# STM32L562 register map
File version: 1.0
CPU: CM33 r0p1, little endian, MPU, FPU, 3 interrupt priority bits
Registers are 32-bit, read-write, reset 0x0 unless marked. A register's access mark holds for its fields unless they carry their own. Offsets are from the block's base; [hi:lo] are bit positions; {n}, {i} and the like mark numbered series.

## GTZC_MPCBB1
Base 0x40032C00
Same registers: GTZC_MPCBB2 0x40033000, SEC_GTZC_MPCBB1 0x50032C00, SEC_GTZC_MPCBB2 0x50033000
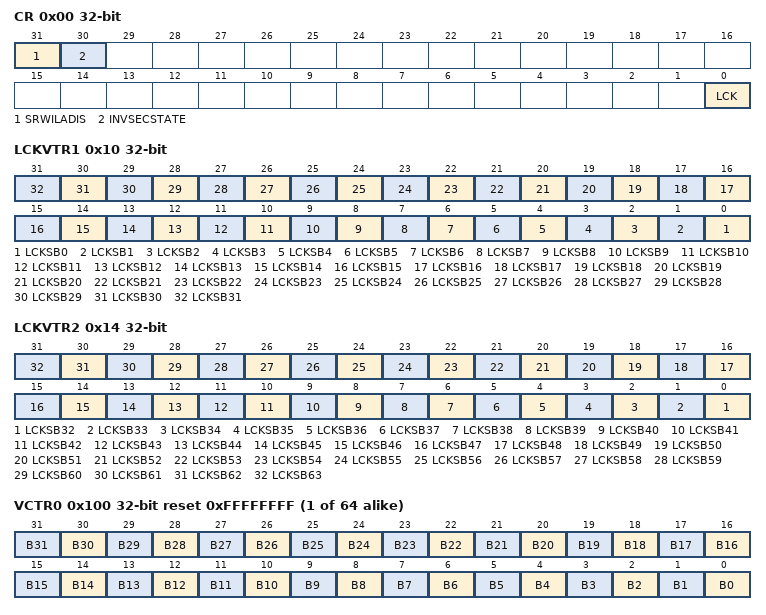
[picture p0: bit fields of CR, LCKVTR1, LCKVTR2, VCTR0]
0x00 CR — MPCBB control register
  [31] SRWILADIS, [30] INVSECSTATE, [0] LCK
0x10 LCKVTR1 — MPCBB control register
  [n] LCKSB{n} (n=0..31)
0x14 LCKVTR2 — MPCBB control register
  [n-32] LCKSB{n} (n=32..63)
{0x100+4i} VCTR{i} (i=0..63) reset 0xFFFFFFFF — MPCBBx vector register
  [n] B{n} (n=0..31)

## GTZC_TZIC
Base 0x40032800
Same registers: SEC_GTZC_TZIC 0x50032800
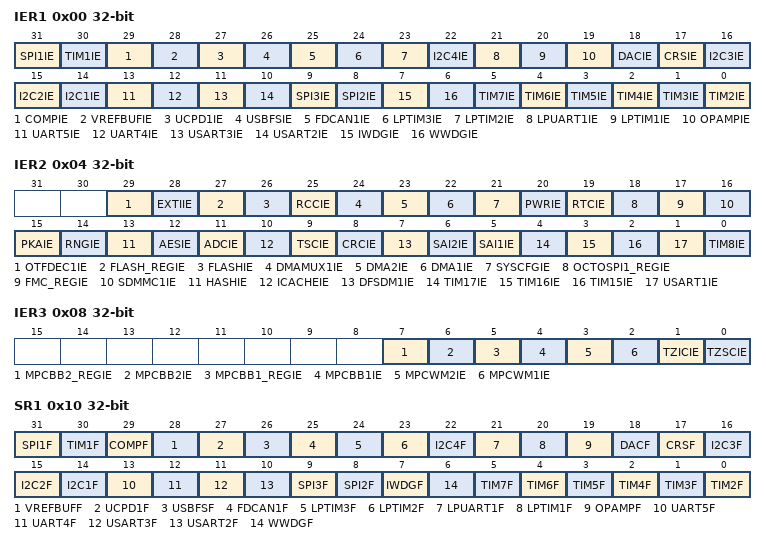
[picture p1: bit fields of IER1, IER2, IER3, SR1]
0x00 IER1 — TZIC interrupt enable register 1
  [31] SPI1IE, [30] TIM1IE, [29] COMPIE, [28] VREFBUFIE, [27] UCPD1IE, [26] USBFSIE, [25] FDCAN1IE, [24] LPTIM3IE, [23] LPTIM2IE, [22] I2C4IE, [21] LPUART1IE, [20] LPTIM1IE, [19] OPAMPIE, [18] DACIE, [17] CRSIE, [16] I2C3IE, [15] I2C2IE, [14] I2C1IE, [13] UART5IE, [12] UART4IE, [11] USART3IE, [10] USART2IE, [9] SPI3IE, [8] SPI2IE, [7] IWDGIE, [6] WWDGIE, [n-2] TIM{n}IE (n=2..7)
0x04 IER2 — TZIC interrupt enable register 2
  [29] OTFDEC1IE, [28] EXTIIE, [27] FLASH_REGIE, [26] FLASHIE, [25] RCCIE, [24] DMAMUX1IE, [23] DMA2IE, [22] DMA1IE, [21] SYSCFGIE, [20] PWRIE, [19] RTCIE, [18] OCTOSPI1_REGIE, [17] FMC_REGIE, [16] SDMMC1IE, [15] PKAIE, [14] RNGIE, [13] HASHIE, [12] AESIE, [11] ADCIE, [10] ICACHEIE, [9] TSCIE, [8] CRCIE, [7] DFSDM1IE, [6] SAI2IE, [5] SAI1IE, [4] TIM17IE, [3] TIM16IE, [2] TIM15IE, [1] USART1IE, [0] TIM8IE
0x08 IER3 — TZIC interrupt enable register 3
  [7] MPCBB2_REGIE, [6] MPCBB2IE, [5] MPCBB1_REGIE, [4] MPCBB1IE, [3] MPCWM2IE, [2] MPCWM1IE, [1] TZICIE, [0] TZSCIE
0x10 SR1 ro — TZIC interrupt status register 1
  [31] SPI1F, [30] TIM1F, [29] COMPF, [28] VREFBUFF, [27] UCPD1F, [26] USBFSF, [25] FDCAN1F, [24] LPTIM3F, [23] LPTIM2F, [22] I2C4F, [21] LPUART1F, [20] LPTIM1F, [19] OPAMPF, [18] DACF, [17] CRSF, [16] I2C3F, [15] I2C2F, [14] I2C1F, [13] UART5F, [12] UART4F, [11] USART3F, [10] USART2F, [9] SPI3F, [8] SPI2F, [7] IWDGF, [6] WWDGF, [n-2] TIM{n}F (n=2..7)
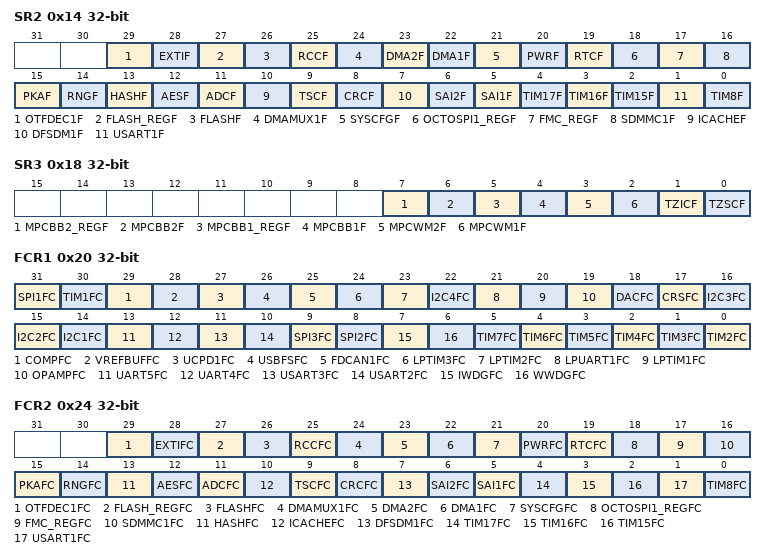
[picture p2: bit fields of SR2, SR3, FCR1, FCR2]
0x14 SR2 — TZIC interrupt status register 2
  [29] OTFDEC1F, [28] EXTIF, [27] FLASH_REGF, [26] FLASHF, [25] RCCF, [24] DMAMUX1F, [23] DMA2F, [22] DMA1F, [21] SYSCFGF, [20] PWRF, [19] RTCF, [18] OCTOSPI1_REGF, [17] FMC_REGF, [16] SDMMC1F, [15] PKAF, [14] RNGF, [13] HASHF, [12] AESF, [11] ADCF, [10] ICACHEF, [9] TSCF, [8] CRCF, [7] DFSDM1F, [6] SAI2F, [5] SAI1F, [4] TIM17F, [3] TIM16F, [2] TIM15F, [1] USART1F, [0] TIM8F
0x18 SR3 — TZIC interrupt status register 3
  [7] MPCBB2_REGF, [6] MPCBB2F, [5] MPCBB1_REGF, [4] MPCBB1F, [3] MPCWM2F, [2] MPCWM1F, [1] TZICF, [0] TZSCF
0x20 FCR1 wo — TZIC interrupt clear register 1
  [31] SPI1FC, [30] TIM1FC, [29] COMPFC, [28] VREFBUFFC, [27] UCPD1FC, [26] USBFSFC, [25] FDCAN1FC, [24] LPTIM3FC, [23] LPTIM2FC, [22] I2C4FC, [21] LPUART1FC, [20] LPTIM1FC, [19] OPAMPFC, [18] DACFC, [17] CRSFC, [16] I2C3FC, [15] I2C2FC, [14] I2C1FC, [13] UART5FC, [12] UART4FC, [11] USART3FC, [10] USART2FC, [9] SPI3FC, [8] SPI2FC, [7] IWDGFC, [6] WWDGFC, [n-2] TIM{n}FC (n=2..7)
0x24 FCR2 — TZIC interrupt clear register 2
  [29] OTFDEC1FC, [28] EXTIFC, [27] FLASH_REGFC, [26] FLASHFC, [25] RCCFC, [24] DMAMUX1FC, [23] DMA2FC, [22] DMA1FC, [21] SYSCFGFC, [20] PWRFC, [19] RTCFC, [18] OCTOSPI1_REGFC, [17] FMC_REGFC, [16] SDMMC1FC, [15] PKAFC, [14] RNGFC, [13] HASHFC, [12] AESFC, [11] ADCFC, [10] ICACHEFC, [9] TSCFC, [8] CRCFC, [7] DFSDM1FC, [6] SAI2FC, [5] SAI1FC, [4] TIM17FC, [3] TIM16FC, [2] TIM15FC, [1] USART1FC, [0] TIM8FC
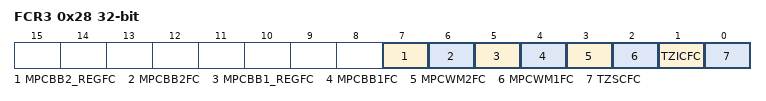
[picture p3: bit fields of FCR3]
0x28 FCR3 — TZIC interrupt clear register 3
  [7] MPCBB2_REGFC, [6] MPCBB2FC, [5] MPCBB1_REGFC, [4] MPCBB1FC, [3] MPCWM2FC, [2] MPCWM1FC, [1] TZICFC, [0] TZSCFC

## GTZC_TZSC
Base 0x40032400
Same registers: SEC_GTZC_TZSC 0x50032400
0x00 CR — TZSC control register
  [0] LCK
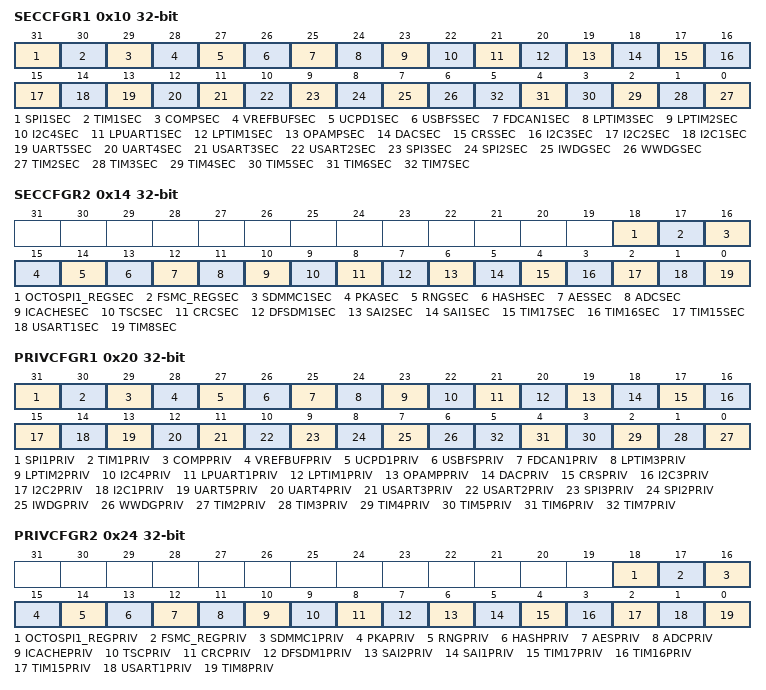
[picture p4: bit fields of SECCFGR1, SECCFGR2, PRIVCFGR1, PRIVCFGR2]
0x10 SECCFGR1 — TZSC secure configuration register 1
  [31] SPI1SEC, [30] TIM1SEC, [29] COMPSEC, [28] VREFBUFSEC, [27] UCPD1SEC, [26] USBFSSEC, [25] FDCAN1SEC, [24] LPTIM3SEC, [23] LPTIM2SEC, [22] I2C4SEC, [21] LPUART1SEC, [20] LPTIM1SEC, [19] OPAMPSEC, [18] DACSEC, [17] CRSSEC, [16] I2C3SEC, [15] I2C2SEC, [14] I2C1SEC, [13] UART5SEC, [12] UART4SEC, [11] USART3SEC, [10] USART2SEC, [9] SPI3SEC, [8] SPI2SEC, [7] IWDGSEC, [6] WWDGSEC, [n-2] TIM{n}SEC (n=2..7)
0x14 SECCFGR2 — TZSC secure configuration register 2
  [18] OCTOSPI1_REGSEC, [17] FSMC_REGSEC, [16] SDMMC1SEC, [15] PKASEC, [14] RNGSEC, [13] HASHSEC, [12] AESSEC, [11] ADCSEC, [10] ICACHESEC, [9] TSCSEC, [8] CRCSEC, [7] DFSDM1SEC, [6] SAI2SEC, [5] SAI1SEC, [4] TIM17SEC, [3] TIM16SEC, [2] TIM15SEC, [1] USART1SEC, [0] TIM8SEC
0x20 PRIVCFGR1 — TZSC privilege configuration register 1
  [31] SPI1PRIV, [30] TIM1PRIV, [29] COMPPRIV, [28] VREFBUFPRIV, [27] UCPD1PRIV, [26] USBFSPRIV, [25] FDCAN1PRIV, [24] LPTIM3PRIV, [23] LPTIM2PRIV, [22] I2C4PRIV, [21] LPUART1PRIV, [20] LPTIM1PRIV, [19] OPAMPPRIV, [18] DACPRIV, [17] CRSPRIV, [16] I2C3PRIV, [15] I2C2PRIV, [14] I2C1PRIV, [13] UART5PRIV, [12] UART4PRIV, [11] USART3PRIV, [10] USART2PRIV, [9] SPI3PRIV, [8] SPI2PRIV, [7] IWDGPRIV, [6] WWDGPRIV, [n-2] TIM{n}PRIV (n=2..7)
0x24 PRIVCFGR2 — TZSC privilege configuration register 2
  [18] OCTOSPI1_REGPRIV — OCTOSPI1_REGRIV
  [17] FSMC_REGPRIV
  [16] SDMMC1PRIV
  [15] PKAPRIV
  [14] RNGPRIV
  [13] HASHPRIV
  [12] AESPRIV
  [11] ADCPRIV
  [10] ICACHEPRIV
  [9] TSCPRIV
  [8] CRCPRIV
  [7] DFSDM1PRIV
  [6] SAI2PRIV
  [5] SAI1PRIV
  [4] TIM17PRIV
  [3] TIM16PRIV
  [2] TIM15PRIV
  [1] USART1PRIV
  [0] TIM8PRIV
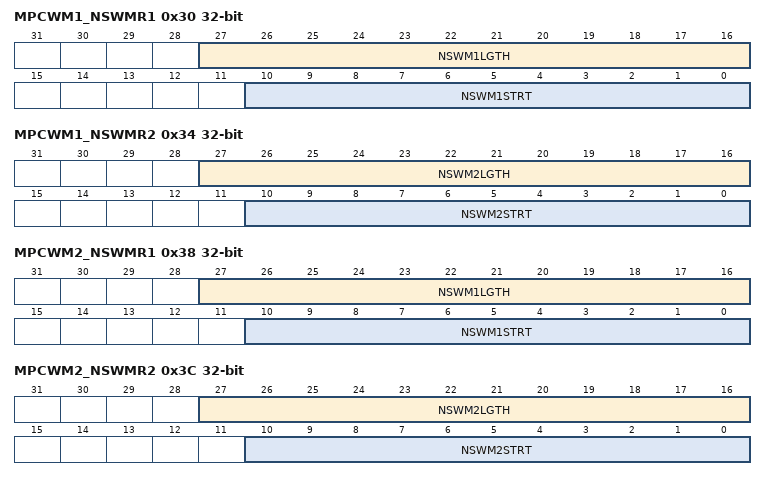
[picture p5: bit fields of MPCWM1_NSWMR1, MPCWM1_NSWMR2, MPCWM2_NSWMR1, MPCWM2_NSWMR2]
0x30 MPCWM1_NSWMR1 — TZSC external memory non-secure watermark register 1
  [27:16] NSWM1LGTH, [10:0] NSWM1STRT
0x34 MPCWM1_NSWMR2 — TZSC external memory non-secure watermark register 1
  [27:16] NSWM2LGTH, [10:0] NSWM2STRT
0x38 MPCWM2_NSWMR1 — TZSC external memory non-secure watermark register 1
  [27:16] NSWM1LGTH, [10:0] NSWM1STRT
0x3C MPCWM2_NSWMR2 — TZSC external memory non-secure watermark register 2
  [27:16] NSWM2LGTH, [10:0] NSWM2STRT
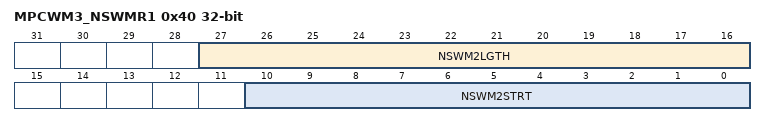
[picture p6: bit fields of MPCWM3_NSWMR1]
0x40 MPCWM3_NSWMR1 — TZSC external memory non-secure watermark register 2
  [27:16] NSWM2LGTH, [10:0] NSWM2STRT
